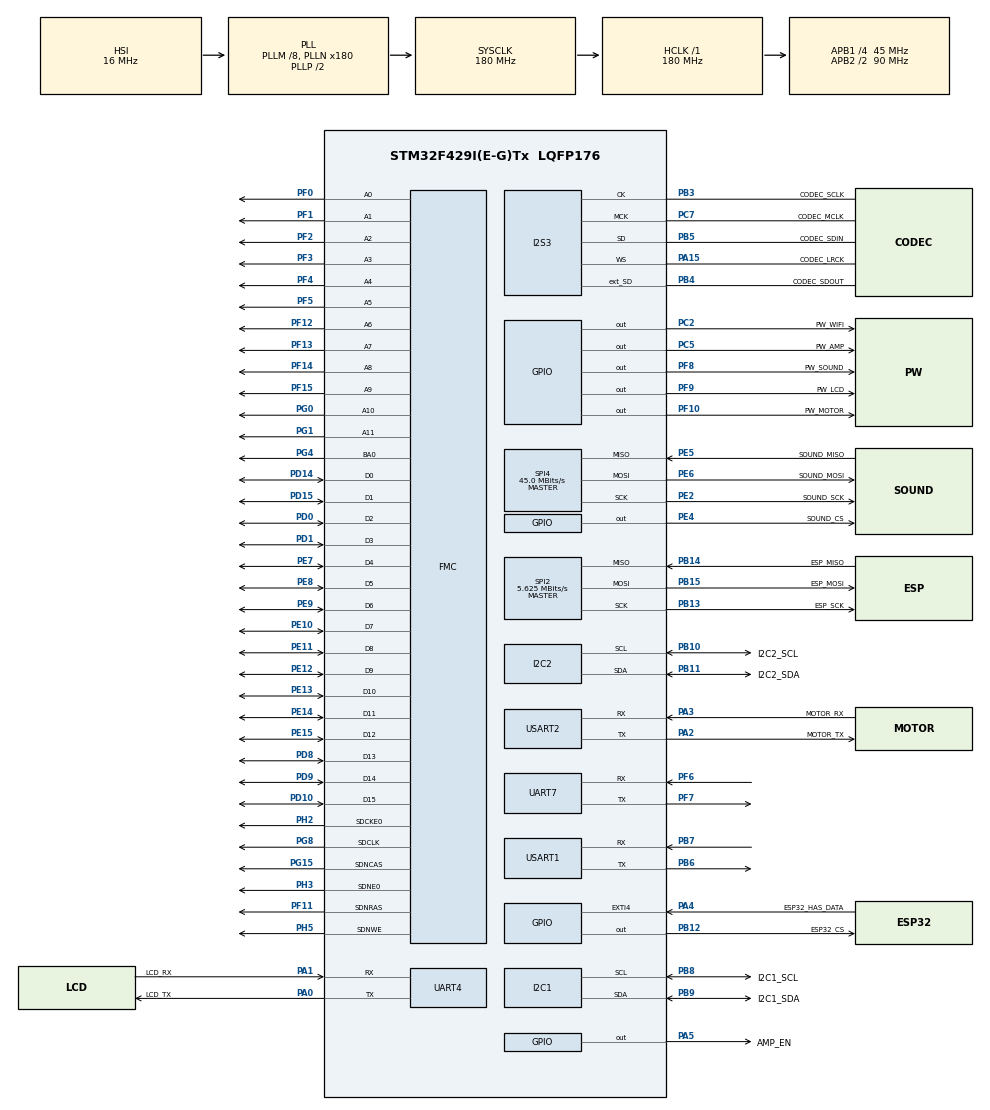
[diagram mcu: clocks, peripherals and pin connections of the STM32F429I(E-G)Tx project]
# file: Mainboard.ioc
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Dma.UART7_TX.4.Priority=DMA_PRIORITY_LOW
Dma.UART7_TX.4.FIFOMode=DMA_FIFOMODE_DISABLE
SH.FMC_D7_DA7.0=FMC_D7,sd-16b-d1
Dma.I2S3_EXT_RX.0.MemDataAlignment=DMA_MDATAALIGN_HALFWORD
SPI4.VirtualType=VM_MASTER
FMC.RCDDelay1=2
FMC.SDClockPeriod1=FMC_SDRAM_CLOCK_PERIOD_3
SH.FMC_A0.0=FMC_A0,12b-sda1
SPI2.VirtualType=VM_MASTER
PB10.Mode=I2C
PG4.Signal=FMC_A14_BA0
PG8.Signal=FMC_SDCLK
PB14.GPIO_Label=ESP_MISO
PG0.Signal=FMC_A10
PA3.GPIO_PuPd=GPIO_PULLUP
FMC.LoadToActiveDelay1=2
SH.FMC_D5_DA5.0=FMC_D5,sd-16b-d1
PB13.Signal=SPI2_SCK
PB3.GPIO_Speed=GPIO_SPEED_FREQ_HIGH
PE6.GPIO_Label=SOUND_MOSI
RCC.SYSCLKSource=RCC_SYSCLKSOURCE_PLLCLK
SH.FMC_D9_DA9.0=FMC_D9,sd-16b-d1
Dma.I2S3_EXT_RX.0.Direction=DMA_PERIPH_TO_MEMORY
PH5.Signal=FMC_SDNWE
PF7.Signal=UART7_TX
SH.FMC_SDNWE.0=FMC_SDNWE,12b-sda1
Dma.SPI2_RX.2.Direction=DMA_PERIPH_TO_MEMORY
SH.FMC_D11_DA11.0=FMC_D11,sd-16b-d1
Dma.UART7_TX.4.Mode=DMA_NORMAL
PE2.Mode=Full_Duplex_Master
RCC.APB2TimFreq_Value=180000000
PB6.Signal=USART1_TX
PC7.Signal=I2S3_MCK
PB12.PinState=GPIO_PIN_SET
PB6.Mode=Asynchronous
PD0.Signal=FMC_D2_DA2
PD8.Signal=FMC_D13_DA13
PE5.Signal=SPI4_MISO
Dma.I2S3_EXT_RX.0.Mode=DMA_CIRCULAR
PF10.GPIO_Label=PW_MOTOR
Dma.SPI2_RX.2.MemDataAlignment=DMA_MDATAALIGN_BYTE
Dma.UART7_TX.4.MemDataAlignment=DMA_MDATAALIGN_BYTE
PB3.Mode=Full_Duplex_Master
Dma.SPI2_RX.2.PeriphInc=DMA_PINC_DISABLE
PB12.GPIO_Label=ESP32_CS
FMC.SelfRefreshTime1=4
I2S3.ErrorAudioFreq=1.72 %
PE9.Signal=FMC_D6_DA6
SH.FMC_A2.0=FMC_A2,12b-sda1
PB14.Mode=Full_Duplex_Master
NVIC.TIM2_IRQn=true\:0\:0\:false\:false\:true\:false\:false\:true
PE4.GPIO_Label=SOUND_CS
SPI2.CalculateBaudRate=5.625 MBits/s
PE2.Signal=SPI4_SCK
Dma.SPI2_RX.2.PeriphDataAlignment=DMA_PDATAALIGN_BYTE
SH.FMC_D1_DA1.0=FMC_D1,sd-16b-d1
PF3.Signal=FMC_A3
PE10.Signal=FMC_D7_DA7
Dma.UART7_TX.4.Direction=DMA_MEMORY_TO_PERIPH
Mcu.Package=LQFP176
PB9.Signal=I2C1_SDA
VP_SYS_VS_tim2.Mode=TIM2
NVIC.TimeBase=TIM2_IRQn
SPI2.Mode=SPI_MODE_MASTER
Dma.SPI2_RX.2.MemInc=DMA_MINC_ENABLE
NVIC.TimeBaseIP=TIM2
SH.FMC_A1.0=FMC_A1,12b-sda1
PB5.GPIO_Speed=GPIO_SPEED_FREQ_HIGH
PH2.Signal=FMC_SDCKE0
RCC.APB2CLKDivider=RCC_HCLK_DIV2
SH.FMC_SDCLK.0=FMC_SDCLK,12b-sda1
PF14.Signal=FMC_A8
RCC.APB1TimFreq_Value=90000000
Dma.I2S3_EXT_RX.0.Priority=DMA_PRIORITY_LOW
PB13.Mode=Full_Duplex_Master
PA4.GPIO_Label=ESP32_HAS_DATA
PD15.Signal=FMC_D1_DA1
SH.FMC_D3_DA3.0=FMC_D3,sd-16b-d1
Dma.SPI2_TX.3.MemInc=DMA_MINC_ENABLE
Dma.SPI3_TX.1.MemInc=DMA_MINC_ENABLE
NVIC.EXTI4_IRQn=true\:15\:0\:true\:false\:true\:true\:true\:true
SH.FMC_A4.0=FMC_A4,12b-sda1
I2S3.FullDuplexMode=I2S_FULLDUPLEXMODE_ENABLE
Dma.I2S3_EXT_RX.0.Instance=DMA1_Stream0
FREERTOS.Tasks01=defaultTask,24,512,StartDefaultTask,Default,NULL,Dynamic,NULL,NULL
SH.FMC_D10_DA10.0=FMC_D10,sd-16b-d1
PC2.Signal=GPIO_Output
PB11.GPIO_Label=I2C2_SDA
PD1.Signal=FMC_D3_DA3
Dma.SPI3_TX.1.Priority=DMA_PRIORITY_LOW
RCC.APB1CLKDivider=RCC_HCLK_DIV4
UART4.VirtualMode=Asynchronous
PF8.GPIO_Label=PW_SOUND
Dma.SPI2_TX.3.PeriphDataAlignment=DMA_PDATAALIGN_BYTE
PD10.Signal=FMC_D15_DA15
PA3.Mode=Asynchronous
SH.FMC_A3.0=FMC_A3,12b-sda1
PB8.GPIO_Label=I2C1_SCL
FMC.CASLatency1=FMC_SDRAM_CAS_LATENCY_3
Dma.UART7_TX.4.PeriphInc=DMA_PINC_DISABLE
PB11.Mode=I2C
Dma.SPI2_RX.2.FIFOMode=DMA_FIFOMODE_DISABLE
SH.FMC_D15_DA15.0=FMC_D15,sd-16b-d1
Dma.I2S3_EXT_RX.0.PeriphInc=DMA_PINC_DISABLE
Dma.SPI3_TX.1.MemDataAlignment=DMA_MDATAALIGN_HALFWORD
I2S3.VirtualMode=I2S_MODE_MASTER
PA4.GPIO_ModeDefaultEXTI=GPIO_MODE_IT_RISING
Dma.I2S3_EXT_RX.0.FIFOMode=DMA_FIFOMODE_DISABLE
Dma.SPI2_TX.3.Mode=DMA_NORMAL
PA0/WKUP.Mode=Asynchronous
PB10.Signal=I2C2_SCL
PB14.Signal=SPI2_MISO
PA5.Signal=GPIO_Output
I2S3.AudioFreq=I2S_AUDIOFREQ_16K
FMC.ReadBurst1=FMC_SDRAM_RBURST_ENABLE
SH.FMC_A6.0=FMC_A6,12b-sda1
Dma.SPI2_TX.3.Instance=DMA1_Stream4
PA1.Mode=Asynchronous
PE14.Signal=FMC_D11_DA11
PE6.Mode=Full_Duplex_Master
PE15.Signal=FMC_D12_DA12
PB4.GPIO_Label=CODEC_SDOUT
PB15.GPIO_Label=ESP_MOSI
PE8.Signal=FMC_D5_DA5
PA1.GPIO_Label=LCD_RX
PA0/WKUP.GPIO_Label=LCD_TX
PF13.Signal=FMC_A7
PA13.Mode=Serial_Wire
SH.FMC_SDNCAS.0=FMC_SDNCAS,12b-sda1
PE4.GPIO_PuPd=GPIO_PULLUP
PC7.GPIO_Label=CODEC_MCLK
Dma.SPI3_TX.1.PeriphInc=DMA_PINC_DISABLE
PA4.Signal=GPXTI4
PB5.Signal=I2S3_SD
PA5.GPIO_Label=AMP_EN
PE5.GPIO_Label=SOUND_MISO
USART1.VirtualMode=VM_ASYNC
SH.FMC_A5.0=FMC_A5,12b-sda1
ProjectManager.HeapSize=0x200
PF6.Mode=Asynchronous
PF9.Signal=GPIO_Output
NVIC.PriorityGroup=NVIC_PRIORITYGROUP_4
PB8.Mode=I2C
Dma.SPI2_TX.3.PeriphInc=DMA_PINC_DISABLE
Dma.SPI2_TX.3.FIFOMode=DMA_FIFOMODE_DISABLE
PF4.Signal=FMC_A4
Dma.UART7_TX.4.Instance=DMA1_Stream1
I2S3.Instance=SPI$Index
PB12.GPIO_PuPd=GPIO_PULLUP
Mcu.Family=STM32F4
PA2.GPIO_PuPd=GPIO_PULLUP
SH.FMC_A8.0=FMC_A8,12b-sda1
RCC.CortexFreq_Value=180000000
SH.FMC_D14_DA14.0=FMC_D14,sd-16b-d1
SPI4.Direction=SPI_DIRECTION_2LINES
SH.FMC_D6_DA6.0=FMC_D6,sd-16b-d1
PA0/WKUP.Signal=UART4_TX
SH.FMC_A14_BA0.0=FMC_BA0,TwoSdramBanks1
SH.FMC_A11.0=FMC_A11,12b-sda1
PB13.GPIO_Label=ESP_SCK
PB11.Signal=I2C2_SDA
NVIC.DMA1_Stream4_IRQn=true\:5\:0\:false\:false\:true\:true\:false\:true
PB15.Signal=SPI2_MOSI
PG15.Signal=FMC_SDNCAS
ProjectManager.StackSize=0x400
VP_FREERTOS_VS_CMSIS_V2.Mode=CMSIS_V2
PH3.Mode=SdramChipSelect1_1
PA15.GPIO_Label=CODEC_LRCK
SH.FMC_A7.0=FMC_A7,12b-sda1
SPI4.Mode=SPI_MODE_MASTER
RCC.HCLKFreq_Value=180000000
PF12.Signal=FMC_A6
Dma.SPI2_TX.3.Priority=DMA_PRIORITY_LOW
SH.FMC_A10.0=FMC_A10,12b-sda1
RCC.AHBFreq_Value=180000000
SPI2.BaudRatePrescaler=SPI_BAUDRATEPRESCALER_8
Dma.SPI2_RX.2.Instance=DMA1_Stream3
RCC.HSE_VALUE=8000000
PA4.GPIO_PuPd=GPIO_PULLUP
SH.FMC_D8_DA8.0=FMC_D8,sd-16b-d1
FMC.ExitSelfRefreshDelay1=7
FMC.RPDelay1=2
PA15.Mode=Full_Duplex_Master
SH.FMC_D2_DA2.0=FMC_D2,sd-16b-d1
PB4.Mode=Full_Duplex_Master
PE13.Signal=FMC_D10_DA10
PA14.Mode=Serial_Wire
PF11.Signal=FMC_SDNRAS
PB5.Mode=Full_Duplex_Master
PB7.Signal=USART1_RX
NVIC.SPI2_IRQn=true\:5\:0\:false\:false\:true\:true\:true\:true
FMC.ReadPipeDelay1=FMC_SDRAM_RPIPE_DELAY_2
SH.FMC_SDNRAS.0=FMC_SDNRAS,12b-sda1
PE4.Signal=GPIO_Output
SPI4.BaudRatePrescaler=SPI_BAUDRATEPRESCALER_2
FREERTOS.configTOTAL_HEAP_SIZE=131072
SH.FMC_D0_DA0.0=FMC_D0,sd-16b-d1
Dma.SPI2_RX.2.Priority=DMA_PRIORITY_LOW
USART2.VirtualMode=VM_ASYNC
Dma.I2S3_EXT_RX.0.MemInc=DMA_MINC_ENABLE
PA2.GPIO_Label=MOTOR_TX
SH.FMC_A9.0=FMC_A9,12b-sda1
PA15.Signal=I2S3_WS
PF8.Signal=GPIO_Output
SH.FMC_D4_DA4.0=FMC_D4,sd-16b-d1
NVIC.SPI3_IRQn=true\:5\:0\:false\:false\:true\:true\:true\:true
SPI2.CLKPhase=SPI_PHASE_2EDGE
PF5.Signal=FMC_A5
Dma.SPI3_TX.1.Direction=DMA_MEMORY_TO_PERIPH
PB5.GPIO_Label=CODEC_SDIN
Dma.Request2=SPI2_RX
Dma.Request1=SPI3_TX
Dma.Request4=UART7_TX
Dma.Request3=SPI2_TX
NVIC.DMA1_Stream0_IRQn=true\:15\:0\:true\:false\:true\:true\:false\:true
SPI2.Direction=SPI_DIRECTION_2LINES
PF0.Signal=FMC_A0
PC5.Signal=GPIO_Output
PH2.Mode=SdramChipSelect1_1
PE7.Signal=FMC_D4_DA4
Dma.Request0=I2S3_EXT_RX
PE2.GPIO_Label=SOUND_SCK
PC2.GPIO_Label=PW_WIFI
Dma.SPI2_TX.3.Direction=DMA_MEMORY_TO_PERIPH
Dma.I2S3_EXT_RX.0.PeriphDataAlignment=DMA_PDATAALIGN_HALFWORD
PB4.Signal=I2S3_ext_SD
PA3.Signal=USART2_RX
PB3.GPIO_Label=CODEC_SCLK
PB9.GPIO_Label=I2C1_SDA
Dma.SPI2_TX.3.MemDataAlignment=DMA_MDATAALIGN_BYTE
PG1.Signal=FMC_A11
Dma.SPI3_TX.1.FIFOMode=DMA_FIFOMODE_DISABLE
PD9.Signal=FMC_D14_DA14
NVIC.DMA1_Stream1_IRQn=true\:5\:0\:false\:false\:true\:true\:false\:true
UART7.VirtualMode=Asynchronous
NVIC.USART2_IRQn=true\:5\:0\:true\:false\:true\:true\:true\:true
Dma.SPI3_TX.1.Instance=DMA1_Stream5
Dma.SPI2_RX.2.Mode=DMA_NORMAL
Dma.SPI3_TX.1.PeriphDataAlignment=DMA_PDATAALIGN_HALFWORD
PA13.Signal=SYS_JTMS-SWDIO
PF7.Mode=Asynchronous
PF6.Signal=UART7_RX
Dma.SPI3_TX.1.Mode=DMA_CIRCULAR
ProjectManager.TargetToolchain=MDK-ARM V5.27
PB10.GPIO_Label=I2C2_SCL
NVIC.DMA1_Stream5_IRQn=true\:15\:0\:true\:false\:true\:true\:false\:true
SH.FMC_D13_DA13.0=FMC_D13,sd-16b-d1
PB9.Mode=I2C
PF2.Signal=FMC_A2
PF9.GPIO_Label=PW_LCD
PE11.Signal=FMC_D8_DA8
RCC.LSE_VALUE=32768
PA1.Signal=UART4_RX
PB12.GPIO_Speed=GPIO_SPEED_FREQ_VERY_HIGH
board=custom
PC7.GPIO_Speed=GPIO_SPEED_FREQ_HIGH
RCC.VCOOutputFreq_Value=360000000
PB15.Mode=Full_Duplex_Master
PB4.GPIO_Speed=GPIO_SPEED_FREQ_HIGH
RCC.APB2Freq_Value=90000000
Dma.UART7_TX.4.PeriphDataAlignment=DMA_PDATAALIGN_BYTE
PF10.Signal=GPIO_Output
PE5.Mode=Full_Duplex_Master
SH.FMC_D12_DA12.0=FMC_D12,sd-16b-d1
PF15.Signal=FMC_A9
SPI4.CalculateBaudRate=45.0 MBits/s
PF1.Signal=FMC_A1
PE6.Signal=SPI4_MOSI
Mcu.Name=STM32F429I(E-G)Tx
PE12.Signal=FMC_D9_DA9
PA2.Signal=USART2_TX
PD14.Signal=FMC_D0_DA0
RCC.48MHZClocksFreq_Value=90000000
PB3.Signal=I2S3_CK
RCC.SYSCLKFreq_VALUE=180000000
PC5.GPIO_Label=PW_AMP
PA15.GPIO_Speed=GPIO_SPEED_FREQ_HIGH
PB7.Mode=Asynchronous
PA14.Signal=SYS_JTCK-SWCLK
RCC.HSI_VALUE=16000000
Dma.UART7_TX.4.MemInc=DMA_MINC_ENABLE
PH3.Signal=FMC_SDNE0
I2S3.RealAudioFreq=16.276 KHz
RCC.PLLM=8
RCC.PLLN=180
PB8.Signal=I2C1_SCL
PA2.Mode=Asynchronous
NVIC.DMA1_Stream3_IRQn=true\:5\:0\:false\:false\:true\:true\:false\:true
PC7.Mode=Master_Clock_Activated
RCC.APB1Freq_Value=45000000
RCC.PLLI2SN=50
PB12.Signal=GPIO_Output
PA3.GPIO_Label=MOTOR_RX
NVIC.UART7_IRQn=true\:5\:0\:false\:false\:true\:true\:true\:true

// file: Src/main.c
/* USER CODE BEGIN Header */
/**
  ******************************************************************************
  * @file           : main.c
  * @brief          : Main program body
  ******************************************************************************
  * @attention
  *
  * <h2><center>&copy; Copyright (c) 2020 STMicroelectronics.
  * All rights reserved.</center></h2>
  *
  * This software component is licensed by ST under Ultimate Liberty license
  * SLA0044, the "License"; You may not use this file except in compliance with
  * the License. You may obtain a copy of the License at:
  *                             www.st.com/SLA0044
  *
  ******************************************************************************
  */
/* USER CODE END Header */

#include "main.h"
#include "cmsis_os.h"

/* USER CODE BEGIN Includes */
#include "command.h"
#include "constant.h"
#include "esp32.h"
#include "direction.h"
#include "log.h"
#include "lcd.h"
#include "audio_play.h"
#include "motor.h"
#include "voice_command.h"
#include "mfcc.h"
#include "gru.h"
#include "dnn.h"

#ifdef RK_CODEC_ENABLE
#include "es8311.h"
#include "stm32429i_mainboard_audio.h"
#include "Resource/audio_please_repeat.h"
#endif /* RK_CODEC_ENABLE */

#include "SEGGER_RTT.h"
#include "app_cli.h"
#include "vsm_shell.h"
#include "FreeRTOS.h"
#include "stream_buffer.h"
#include "cpu_utils.h"
#include "motor.h"
#include "esp32.h"
#include "voice_command.h"
#include "rk_serial_protocol.h"
#include "rk_serial_protocol_id.h"

/* USER CODE END Includes */

/* USER CODE BEGIN PTD */
#define TAG    "main"
#define BUFFER_SIZE         ((uint32_t)0x0100)
#define WRITE_READ_ADDR     ((uint32_t)0x000)
//#define WRITE_READ_ADDR     ((uint32_t)0x004)
#define REFRESH_COUNT       ((uint32_t)0x056A)   /* SDRAM refresh counter (90MHz SDRAM clock) */
/* USER CODE END PTD */

/* USER CODE BEGIN PD */
#define AUDIO_BUFFER_SIZE           16000
#define MAX_AUDIO_LENGTH            64000
#define AUDIO_SPI_RX_BUFFER_SIZE    (16000)
#define DMA_SPI_RX_BUFFER_SIZE      (4092)
#define PING_PONG_TIMEOUT           (10000)
#define ESP32_KEEP_ALIVE_TIMEOUT    (60000)

#define SDRAM_SIZE                  (8*1024*1024)

typedef uint32_t sram_addr_t;

/* USER CODE END PD */

I2C_HandleTypeDef hi2c1;
I2C_HandleTypeDef hi2c2;

I2S_HandleTypeDef hi2s3;
DMA_HandleTypeDef hdma_i2s3_ext_rx;
DMA_HandleTypeDef hdma_spi3_tx;

SPI_HandleTypeDef hspi2;
SPI_HandleTypeDef hspi4;
DMA_HandleTypeDef hdma_spi2_rx;
DMA_HandleTypeDef hdma_spi2_tx;

UART_HandleTypeDef huart4;
UART_HandleTypeDef huart7;
UART_HandleTypeDef huart1;
UART_HandleTypeDef huart2;
DMA_HandleTypeDef hdma_uart7_tx;

SDRAM_HandleTypeDef hsdram1;

/* Definitions for defaultTask */
osThreadId_t defaultTaskHandle;
const osThreadAttr_t defaultTask_attributes = {
  .name = "defaultTask",
  .priority = (osPriority_t) osPriorityNormal,
  .stack_size = 512 * 4
};
/* USER CODE BEGIN PV */
osThreadId_t task_handle_log;
const osThreadAttr_t voice_task_attributes = {
  .name = "voiceCMD",
  .priority = (osPriority_t) osPriorityLow,
  .stack_size = 512 * 4
};
extern int16_t *audio_buffer_in;

/* Read/Write Buffers */
sram_addr_t aTxBuffer[BUFFER_SIZE];
sram_addr_t aRxBuffer[BUFFER_SIZE];
__IO uint32_t uwWriteReadStatus = 0;
static void Fill_Buffer(sram_addr_t *pBuffer, uint32_t uwBufferLenght, sram_addr_t value)
{
    uint32_t tmpIndex = 0;

    /* Put in global buffer different values */
    for (tmpIndex = 0; tmpIndex < uwBufferLenght; tmpIndex++ )
    {
        pBuffer[tmpIndex] = value;
    }
}
static void SDRAM_Initialization_Sequence(SDRAM_HandleTypeDef *hsdram, FMC_SDRAM_CommandTypeDef *Command);
FMC_SDRAM_CommandTypeDef command;

/* Counter index */
uint32_t uwIndex = 0;
/**
 * @brief the buffer stores audio stream
*/
int16_t *audio_buffer_1s;
extern VAD_ResultTypeDef vad_result;

void Assert_Is_NULL(void* value);

/* USER CODE END PV */

void SystemClock_Config(void);
static void MX_GPIO_Init(void);
static void MX_DMA_Init(void);
static void MX_FMC_Init(void);
static void MX_I2C1_Init(void);
static void MX_I2C2_Init(void);
static void MX_SPI2_Init(void);
static void MX_SPI4_Init(void);
static void MX_UART4_Init(void);
static void MX_USART1_UART_Init(void);
static void MX_USART2_UART_Init(void);
static void MX_I2S3_Init(void);
static void MX_UART7_Init(void);
void StartDefaultTask(void *argument);

/* USER CODE BEGIN PFP */
static void task_uart(void * argument);
static void esp32_on_data_callback(uint8_t id, uint8_t len, uint8_t * data);
/* USER CODE END PFP */

/* USER CODE BEGIN 0 */
/**
 * @brief The buffer used to send a command to motor's module
 */
uint8_t Motor_Command_TX[CMD_UART_MAX_LENGTH];

/**
 * @brief The buffer used to send a command to eye's module
 */
uint8_t Eye_Command_TX[CMD_UART_MAX_LENGTH];

static volatile uint32_t success = 0;
static void sdram_test_loop()
{
    vTaskDelay(2000);
    //#define SDRAM_BANK_ADDR 0xD0000000
    #define SDRAM_BANK_ADDR 0xC0000000
    Fill_Buffer(aTxBuffer, BUFFER_SIZE, 0x1234);
    RK_LOGI(TAG, "RAM size %d, test buffer size %d, filter count %d\r\n", SDRAM_SIZE, BUFFER_SIZE*sizeof(sram_addr_t), (SDRAM_SIZE/(BUFFER_SIZE*sizeof(sram_addr_t)) - 1));
    while(1)
    {
        sram_addr_t * pTest = (sram_addr_t*)(SDRAM_BANK_ADDR + WRITE_READ_ADDR);
        for (uint32_t idx = 0; idx < (SDRAM_SIZE/(BUFFER_SIZE*sizeof(sram_addr_t)) - 1); idx++)
        {
          /* Write data to the SDRAM memory */
          for (uwIndex = 0; uwIndex < BUFFER_SIZE; uwIndex++)
          {
            *(__IO sram_addr_t*) (pTest + uwIndex*sizeof(sram_addr_t) + idx*BUFFER_SIZE*sizeof(sram_addr_t)) = aTxBuffer[uwIndex];
          }

          /* Read back data from the SDRAM memory */
          for (uwIndex = 0; uwIndex < BUFFER_SIZE; uwIndex++)
          {
            aRxBuffer[uwIndex] = *(__IO sram_addr_t*) (pTest + uwIndex*sizeof(sram_addr_t) + idx*BUFFER_SIZE*sizeof(sram_addr_t));
           }

          /*##-3- Checking data integrity ############################################*/

    //      for (uwIndex = 0; (uwIndex < BUFFER_SIZE) && (uwWriteReadStatus == 0); uwIndex++)
          for (uwIndex = 0; (uwIndex < BUFFER_SIZE); uwIndex++)
          {
            if (aRxBuffer[uwIndex] != aTxBuffer[uwIndex])
            {
              uwWriteReadStatus++;
            }
          }

          if (uwWriteReadStatus)
          {
            /* KO */
            /* Turn on LED4 */
            RK_LOGI(TAG, "SDRAM verify error count %d\r\n", uwWriteReadStatus);
            assert_failed(__FILE__, __LINE__);
          }
          else
          {
            /* OK */
            /* Turn on LED3 */
              success++;
              static uint32_t j = 0;
              if (j++ == 2000)
              {
                  j = 0;
                  RK_LOGI(TAG, "SDRAM loop : %d\r\n", success);
              }
          }
        }
        vTaskDelay(1);
    }
}

void cli_get_char(void);

/* USER CODE END 0 */

int main(void)
{
  /* USER CODE BEGIN 1 */
    uwTickPrio = TICK_INT_PRIORITY;     // Workaround for stm32 bug
    /* https://community.st.com/s/question/0D50X0000C6duTo/halnvicsetpriority-assert-issue-and-incorrect-preempt-priority-value-for-the-stm32f4-stm32g4- */
  /* USER CODE END 1 */

  /* MCU Configuration--------------------------------------------------------*/

  /* Reset of all peripherals, Initializes the Flash interface and the Systick. */
  HAL_Init();

  /* Configure the system clock */
  SystemClock_Config();

  /* Initialize all configured peripherals */
  MX_GPIO_Init();
  MX_DMA_Init();
  MX_FMC_Init();
  MX_I2C1_Init();
  MX_I2C2_Init();
  MX_SPI2_Init();
  MX_SPI4_Init();
  MX_UART4_Init();
  MX_USART1_UART_Init();
  MX_USART2_UART_Init();
  MX_I2S3_Init();
  MX_UART7_Init();
  /* USER CODE BEGIN 2 */

	audio_buffer_1s = pvPortMalloc(SAMPLE_1_SEC *2);
  Assert_Is_NULL(audio_buffer_1s);

	esp32_spi_communication_initialize();
  KWS_Init();
  /* USER CODE END 2 */

  /* Init scheduler */
  osKernelInitialize();

  /* Create the thread(s) */
  /* creation of defaultTask */
  defaultTaskHandle = osThreadNew(StartDefaultTask, NULL, &defaultTask_attributes);

  /* USER CODE BEGIN RTOS_THREADS */
  task_handle_log = osThreadNew(task_uart, NULL, &voice_task_attributes);

  /* add threads, ... */
  /* USER CODE END RTOS_THREADS */

  /* Start scheduler */
  osKernelStart();

  /* We should never get here as control is now taken by the scheduler */
  /* Infinite loop */
  while (1)
  {

  }
}

void SystemClock_Config(void)
{
  RCC_OscInitTypeDef RCC_OscInitStruct = {0};
  RCC_ClkInitTypeDef RCC_ClkInitStruct = {0};
  RCC_PeriphCLKInitTypeDef PeriphClkInitStruct = {0};

  /** Configure the main internal regulator output voltage
  */
  __HAL_RCC_PWR_CLK_ENABLE();
  __HAL_PWR_VOLTAGESCALING_CONFIG(PWR_REGULATOR_VOLTAGE_SCALE1);
  /** Initializes the CPU, AHB and APB busses clocks
  */
  RCC_OscInitStruct.OscillatorType = RCC_OSCILLATORTYPE_HSI;
  RCC_OscInitStruct.HSIState = RCC_HSI_ON;
  RCC_OscInitStruct.HSICalibrationValue = RCC_HSICALIBRATION_DEFAULT;
  RCC_OscInitStruct.PLL.PLLState = RCC_PLL_ON;
  RCC_OscInitStruct.PLL.PLLSource = RCC_PLLSOURCE_HSI;
  RCC_OscInitStruct.PLL.PLLM = 8;
  RCC_OscInitStruct.PLL.PLLN = 180;
  RCC_OscInitStruct.PLL.PLLP = RCC_PLLP_DIV2;
  RCC_OscInitStruct.PLL.PLLQ = 4;
  if (HAL_RCC_OscConfig(&RCC_OscInitStruct) != HAL_OK)
  {
    Error_Handler();
  }
  /** Activate the Over-Drive mode
  */
  if (HAL_PWREx_EnableOverDrive() != HAL_OK)
  {
    Error_Handler();
  }
  /** Initializes the CPU, AHB and APB busses clocks
  */
  RCC_ClkInitStruct.ClockType = RCC_CLOCKTYPE_HCLK|RCC_CLOCKTYPE_SYSCLK
                              |RCC_CLOCKTYPE_PCLK1|RCC_CLOCKTYPE_PCLK2;
  RCC_ClkInitStruct.SYSCLKSource = RCC_SYSCLKSOURCE_PLLCLK;
  RCC_ClkInitStruct.AHBCLKDivider = RCC_SYSCLK_DIV1;
  RCC_ClkInitStruct.APB1CLKDivider = RCC_HCLK_DIV4;
  RCC_ClkInitStruct.APB2CLKDivider = RCC_HCLK_DIV2;

  if (HAL_RCC_ClockConfig(&RCC_ClkInitStruct, FLASH_LATENCY_5) != HAL_OK)
  {
    Error_Handler();
  }
  PeriphClkInitStruct.PeriphClockSelection = RCC_PERIPHCLK_I2S;
  PeriphClkInitStruct.PLLI2S.PLLI2SN = 50;
  PeriphClkInitStruct.PLLI2S.PLLI2SR = 2;
  if (HAL_RCCEx_PeriphCLKConfig(&PeriphClkInitStruct) != HAL_OK)
  {
    Error_Handler();
  }
}

static void MX_I2C1_Init(void)
{

  hi2c1.Instance = I2C1;
  hi2c1.Init.ClockSpeed = 100000;
  hi2c1.Init.DutyCycle = I2C_DUTYCYCLE_2;
  hi2c1.Init.OwnAddress1 = 0;
  hi2c1.Init.AddressingMode = I2C_ADDRESSINGMODE_7BIT;
  hi2c1.Init.DualAddressMode = I2C_DUALADDRESS_DISABLE;
  hi2c1.Init.OwnAddress2 = 0;
  hi2c1.Init.GeneralCallMode = I2C_GENERALCALL_DISABLE;
  hi2c1.Init.NoStretchMode = I2C_NOSTRETCH_DISABLE;
  if (HAL_I2C_Init(&hi2c1) != HAL_OK)
  {
    Error_Handler();
  }
  /** Configure Analogue filter
  */
  if (HAL_I2CEx_ConfigAnalogFilter(&hi2c1, I2C_ANALOGFILTER_ENABLE) != HAL_OK)
  {
    Error_Handler();
  }
  /** Configure Digital filter
  */
  if (HAL_I2CEx_ConfigDigitalFilter(&hi2c1, 0) != HAL_OK)
  {
    Error_Handler();
  }

}

static void MX_I2C2_Init(void)
{

  hi2c2.Instance = I2C2;
  hi2c2.Init.ClockSpeed = 100000;
  hi2c2.Init.DutyCycle = I2C_DUTYCYCLE_2;
  hi2c2.Init.OwnAddress1 = 0;
  hi2c2.Init.AddressingMode = I2C_ADDRESSINGMODE_7BIT;
  hi2c2.Init.DualAddressMode = I2C_DUALADDRESS_DISABLE;
  hi2c2.Init.OwnAddress2 = 0;
  hi2c2.Init.GeneralCallMode = I2C_GENERALCALL_DISABLE;
  hi2c2.Init.NoStretchMode = I2C_NOSTRETCH_DISABLE;
  if (HAL_I2C_Init(&hi2c2) != HAL_OK)
  {
    Error_Handler();
  }
  /** Configure Analogue filter
  */
  if (HAL_I2CEx_ConfigAnalogFilter(&hi2c2, I2C_ANALOGFILTER_ENABLE) != HAL_OK)
  {
    Error_Handler();
  }
  /** Configure Digital filter
  */
  if (HAL_I2CEx_ConfigDigitalFilter(&hi2c2, 0) != HAL_OK)
  {
    Error_Handler();
  }

}

static void MX_I2S3_Init(void)
{

  hi2s3.Instance = SPI3;
  hi2s3.Init.Mode = I2S_MODE_MASTER_TX;
  hi2s3.Init.Standard = I2S_STANDARD_PHILIPS;
  hi2s3.Init.DataFormat = I2S_DATAFORMAT_16B;
  hi2s3.Init.MCLKOutput = I2S_MCLKOUTPUT_ENABLE;
  hi2s3.Init.AudioFreq = I2S_AUDIOFREQ_16K;
  hi2s3.Init.CPOL = I2S_CPOL_LOW;
  hi2s3.Init.ClockSource = I2S_CLOCK_PLL;
  hi2s3.Init.FullDuplexMode = I2S_FULLDUPLEXMODE_ENABLE;
  if (HAL_I2S_Init(&hi2s3) != HAL_OK)
  {
    Error_Handler();
  }

}

static void MX_SPI2_Init(void)
{

  /* SPI2 parameter configuration*/
  hspi2.Instance = SPI2;
  hspi2.Init.Mode = SPI_MODE_MASTER;
  hspi2.Init.Direction = SPI_DIRECTION_2LINES;
  hspi2.Init.DataSize = SPI_DATASIZE_8BIT;
  hspi2.Init.CLKPolarity = SPI_POLARITY_LOW;
  hspi2.Init.CLKPhase = SPI_PHASE_2EDGE;
  hspi2.Init.NSS = SPI_NSS_SOFT;
  hspi2.Init.BaudRatePrescaler = SPI_BAUDRATEPRESCALER_8;
  hspi2.Init.FirstBit = SPI_FIRSTBIT_MSB;
  hspi2.Init.TIMode = SPI_TIMODE_DISABLE;
  hspi2.Init.CRCCalculation = SPI_CRCCALCULATION_DISABLE;
  hspi2.Init.CRCPolynomial = 10;
  if (HAL_SPI_Init(&hspi2) != HAL_OK)
  {
    Error_Handler();
  }

}

static void MX_SPI4_Init(void)
{

  /* SPI4 parameter configuration*/
  hspi4.Instance = SPI4;
  hspi4.Init.Mode = SPI_MODE_MASTER;
  hspi4.Init.Direction = SPI_DIRECTION_2LINES;
  hspi4.Init.DataSize = SPI_DATASIZE_8BIT;
  hspi4.Init.CLKPolarity = SPI_POLARITY_LOW;
  hspi4.Init.CLKPhase = SPI_PHASE_1EDGE;
  hspi4.Init.NSS = SPI_NSS_SOFT;
  hspi4.Init.BaudRatePrescaler = SPI_BAUDRATEPRESCALER_2;
  hspi4.Init.FirstBit = SPI_FIRSTBIT_MSB;
  hspi4.Init.TIMode = SPI_TIMODE_DISABLE;
  hspi4.Init.CRCCalculation = SPI_CRCCALCULATION_DISABLE;
  hspi4.Init.CRCPolynomial = 10;
  if (HAL_SPI_Init(&hspi4) != HAL_OK)
  {
    Error_Handler();
  }

}

static void MX_UART4_Init(void)
{

  huart4.Instance = UART4;
  huart4.Init.BaudRate = 115200;
  huart4.Init.WordLength = UART_WORDLENGTH_8B;
  huart4.Init.StopBits = UART_STOPBITS_1;
  huart4.Init.Parity = UART_PARITY_NONE;
  huart4.Init.Mode = UART_MODE_TX_RX;
  huart4.Init.HwFlowCtl = UART_HWCONTROL_NONE;
  huart4.Init.OverSampling = UART_OVERSAMPLING_16;
  if (HAL_UART_Init(&huart4) != HAL_OK)
  {
    Error_Handler();
  }

}

static void MX_UART7_Init(void)
{

  huart7.Instance = UART7;
  huart7.Init.BaudRate = 115200;
  huart7.Init.WordLength = UART_WORDLENGTH_8B;
  huart7.Init.StopBits = UART_STOPBITS_1;
  huart7.Init.Parity = UART_PARITY_NONE;
  huart7.Init.Mode = UART_MODE_TX_RX;
  huart7.Init.HwFlowCtl = UART_HWCONTROL_NONE;
  huart7.Init.OverSampling = UART_OVERSAMPLING_16;
  if (HAL_UART_Init(&huart7) != HAL_OK)
  {
    Error_Handler();
  }

}

static void MX_USART1_UART_Init(void)
{

  huart1.Instance = USART1;
  huart1.Init.BaudRate = 115200;
  huart1.Init.WordLength = UART_WORDLENGTH_8B;
  huart1.Init.StopBits = UART_STOPBITS_1;
  huart1.Init.Parity = UART_PARITY_NONE;
  huart1.Init.Mode = UART_MODE_TX_RX;
  huart1.Init.HwFlowCtl = UART_HWCONTROL_NONE;
  huart1.Init.OverSampling = UART_OVERSAMPLING_16;
  if (HAL_UART_Init(&huart1) != HAL_OK)
  {
    Error_Handler();
  }

}

static void MX_USART2_UART_Init(void)
{

  huart2.Instance = USART2;
  huart2.Init.BaudRate = 115200;
  huart2.Init.WordLength = UART_WORDLENGTH_8B;
  huart2.Init.StopBits = UART_STOPBITS_1;
  huart2.Init.Parity = UART_PARITY_NONE;
  huart2.Init.Mode = UART_MODE_TX_RX;
  huart2.Init.HwFlowCtl = UART_HWCONTROL_NONE;
  huart2.Init.OverSampling = UART_OVERSAMPLING_16;
  if (HAL_UART_Init(&huart2) != HAL_OK)
  {
    Error_Handler();
  }

}

static void MX_DMA_Init(void)
{

  /* DMA controller clock enable */
  __HAL_RCC_DMA1_CLK_ENABLE();

  /* DMA interrupt init */
  /* DMA1_Stream0_IRQn interrupt configuration */
  HAL_NVIC_SetPriority(DMA1_Stream0_IRQn, 15, 0);
  HAL_NVIC_EnableIRQ(DMA1_Stream0_IRQn);
  /* DMA1_Stream1_IRQn interrupt configuration */
  HAL_NVIC_SetPriority(DMA1_Stream1_IRQn, 5, 0);
  HAL_NVIC_EnableIRQ(DMA1_Stream1_IRQn);
  /* DMA1_Stream3_IRQn interrupt configuration */
  HAL_NVIC_SetPriority(DMA1_Stream3_IRQn, 5, 0);
  HAL_NVIC_EnableIRQ(DMA1_Stream3_IRQn);
  /* DMA1_Stream4_IRQn interrupt configuration */
  HAL_NVIC_SetPriority(DMA1_Stream4_IRQn, 5, 0);
  HAL_NVIC_EnableIRQ(DMA1_Stream4_IRQn);
  /* DMA1_Stream5_IRQn interrupt configuration */
  HAL_NVIC_SetPriority(DMA1_Stream5_IRQn, 15, 0);
  HAL_NVIC_EnableIRQ(DMA1_Stream5_IRQn);

}

/* FMC initialization function */
static void MX_FMC_Init(void)
{

  /* USER CODE BEGIN FMC_Init 0 */
#if 1
  /* USER CODE END FMC_Init 0 */

  FMC_SDRAM_TimingTypeDef SdramTiming = {0};

  /** Perform the SDRAM1 memory initialization sequence
  */
  hsdram1.Instance = FMC_SDRAM_DEVICE;
  /* hsdram1.Init */
  hsdram1.Init.SDBank = FMC_SDRAM_BANK1;
  hsdram1.Init.ColumnBitsNumber = FMC_SDRAM_COLUMN_BITS_NUM_8;
  hsdram1.Init.RowBitsNumber = FMC_SDRAM_ROW_BITS_NUM_12;
  hsdram1.Init.MemoryDataWidth = FMC_SDRAM_MEM_BUS_WIDTH_16;
  hsdram1.Init.InternalBankNumber = FMC_SDRAM_INTERN_BANKS_NUM_4;
  hsdram1.Init.CASLatency = FMC_SDRAM_CAS_LATENCY_3;
  hsdram1.Init.WriteProtection = FMC_SDRAM_WRITE_PROTECTION_DISABLE;
  hsdram1.Init.SDClockPeriod = FMC_SDRAM_CLOCK_PERIOD_3;
  hsdram1.Init.ReadBurst = FMC_SDRAM_RBURST_ENABLE;
  hsdram1.Init.ReadPipeDelay = FMC_SDRAM_RPIPE_DELAY_2;
  /* SdramTiming */
  SdramTiming.LoadToActiveDelay = 2;
  SdramTiming.ExitSelfRefreshDelay = 7;
  SdramTiming.SelfRefreshTime = 4;
  SdramTiming.RowCycleDelay = 16;
  SdramTiming.WriteRecoveryTime = 16;
  SdramTiming.RPDelay = 2;
  SdramTiming.RCDDelay = 2;

  if (HAL_SDRAM_Init(&hsdram1, &SdramTiming) != HAL_OK)
  {
    Error_Handler( );
  }

  /* USER CODE BEGIN FMC_Init 2 */
  /* Program the SDRAM external device */
  SDRAM_Initialization_Sequence(&hsdram1, &command);
#endif /* SDRAM_ENABLE */
  /* USER CODE END FMC_Init 2 */
}

static void MX_GPIO_Init(void)
{
  GPIO_InitTypeDef GPIO_InitStruct = {0};

  /* GPIO Ports Clock Enable */
  __HAL_RCC_GPIOE_CLK_ENABLE();
  __HAL_RCC_GPIOF_CLK_ENABLE();
  __HAL_RCC_GPIOC_CLK_ENABLE();
  __HAL_RCC_GPIOA_CLK_ENABLE();
  __HAL_RCC_GPIOH_CLK_ENABLE();
  __HAL_RCC_GPIOG_CLK_ENABLE();
  __HAL_RCC_GPIOB_CLK_ENABLE();
  __HAL_RCC_GPIOD_CLK_ENABLE();

  /*Configure GPIO pin Output Level */
  HAL_GPIO_WritePin(SOUND_CS_GPIO_Port, SOUND_CS_Pin, GPIO_PIN_RESET);

  /*Configure GPIO pin Output Level */
  HAL_GPIO_WritePin(GPIOF, PW_SOUND_Pin|PW_LCD_Pin|PW_MOTOR_Pin, GPIO_PIN_RESET);

  /*Configure GPIO pin Output Level */
  HAL_GPIO_WritePin(GPIOC, PW_WIFI_Pin|PW_AMP_Pin, GPIO_PIN_RESET);

  /*Configure GPIO pin Output Level */
  HAL_GPIO_WritePin(AMP_EN_GPIO_Port, AMP_EN_Pin, GPIO_PIN_RESET);

  /*Configure GPIO pin Output Level */
  HAL_GPIO_WritePin(ESP32_CS_GPIO_Port, ESP32_CS_Pin, GPIO_PIN_SET);

  /*Configure GPIO pin : SOUND_CS_Pin */
  GPIO_InitStruct.Pin = SOUND_CS_Pin;
  GPIO_InitStruct.Mode = GPIO_MODE_OUTPUT_PP;
  GPIO_InitStruct.Pull = GPIO_PULLUP;
  GPIO_InitStruct.Speed = GPIO_SPEED_FREQ_LOW;
  HAL_GPIO_Init(SOUND_CS_GPIO_Port, &GPIO_InitStruct);

  /*Configure GPIO pins : PW_SOUND_Pin PW_LCD_Pin PW_MOTOR_Pin */
  GPIO_InitStruct.Pin = PW_SOUND_Pin|PW_LCD_Pin|PW_MOTOR_Pin;
  GPIO_InitStruct.Mode = GPIO_MODE_OUTPUT_PP;
  GPIO_InitStruct.Pull = GPIO_NOPULL;
  GPIO_InitStruct.Speed = GPIO_SPEED_FREQ_LOW;
  HAL_GPIO_Init(GPIOF, &GPIO_InitStruct);

  /*Configure GPIO pins : PW_WIFI_Pin PW_AMP_Pin */
  GPIO_InitStruct.Pin = PW_WIFI_Pin|PW_AMP_Pin;
  GPIO_InitStruct.Mode = GPIO_MODE_OUTPUT_PP;
  GPIO_InitStruct.Pull = GPIO_NOPULL;
  GPIO_InitStruct.Speed = GPIO_SPEED_FREQ_LOW;
  HAL_GPIO_Init(GPIOC, &GPIO_InitStruct);

  /*Configure GPIO pin : ESP32_HAS_DATA_Pin */
  GPIO_InitStruct.Pin = ESP32_HAS_DATA_Pin;
  GPIO_InitStruct.Mode = GPIO_MODE_IT_RISING;
  GPIO_InitStruct.Pull = GPIO_PULLUP;
  HAL_GPIO_Init(ESP32_HAS_DATA_GPIO_Port, &GPIO_InitStruct);

  /*Configure GPIO pin : AMP_EN_Pin */
  GPIO_InitStruct.Pin = AMP_EN_Pin;
  GPIO_InitStruct.Mode = GPIO_MODE_OUTPUT_PP;
  GPIO_InitStruct.Pull = GPIO_NOPULL;
  GPIO_InitStruct.Speed = GPIO_SPEED_FREQ_LOW;
  HAL_GPIO_Init(AMP_EN_GPIO_Port, &GPIO_InitStruct);

  /*Configure GPIO pin : ESP32_CS_Pin */
  GPIO_InitStruct.Pin = ESP32_CS_Pin;
  GPIO_InitStruct.Mode = GPIO_MODE_OUTPUT_PP;
  GPIO_InitStruct.Pull = GPIO_PULLUP;
  GPIO_InitStruct.Speed = GPIO_SPEED_FREQ_VERY_HIGH;
  HAL_GPIO_Init(ESP32_CS_GPIO_Port, &GPIO_InitStruct);

  /* EXTI interrupt init*/
  HAL_NVIC_SetPriority(EXTI4_IRQn, 15, 0);
  HAL_NVIC_EnableIRQ(EXTI4_IRQn);

}

/* USER CODE BEGIN 4 */

void cli_get_char()
{
    int key = SEGGER_RTT_GetKey();
    if (key < 0)
    {
        return;
    }
    uint8_t val = (uint8_t)key;
    cli_input_insert(&val, 1);
}

void HAL_GPIO_EXTI_Callback(uint16_t GPIO_Pin) {
    if (GPIO_Pin == GPIO_PIN_4)
    {
//        RK_LOGI(TAG, "Handshake level %s\r\n", HAL_GPIO_ReadPin(GPIOA, GPIO_PIN_4) ? "high" : "low");
        if (HAL_GPIO_ReadPin(GPIOA, GPIO_PIN_4))
            esp32_notify_slave_ready(true);
        else
            esp32_notify_slave_busy();
    }
}

void HAL_UART_ErrorCallback(UART_HandleTypeDef *huart)
{
    __HAL_UART_CLEAR_OREFLAG(huart);
    __HAL_UART_CLEAR_NEFLAG(huart);
    __HAL_UART_CLEAR_FEFLAG(huart);
//    __HAL_UART_DISABLE_IT(huart, UART_IT_ERR);

    if (huart == &huart7)
    {
        esp32_uart_rx_enable(); //TODO:
    }
    else if (huart == &huart2)
    {
        motor_uart_rx_enable();
    }
    else if (huart == &huart4)
    {
        lcd_uart_rx_enable();
    }
}

void HAL_UART_TxCpltCallback(UART_HandleTypeDef *huart)
{
	if (huart == &huart2)
    {
//		free(huart->pTxBuffPtr);
        motor_cmd_done_cb();
	}
    else if (huart == &huart7)
    {
        esp32_cmd_uart_tx_done();
    }
    else if (huart == &huart4)
    {
        lcd_cmd_done_cb();
    }
}

void HAL_UART_RxCpltCallback(UART_HandleTypeDef *huart)
{
    if (huart == &huart7)
    {
//        uint8_t recv = esp32_communication_get_last_in_data();
        esp32_communication_rx_data(true);
        esp32_uart_rx_enable();
    }
    else
        if (huart == &huart2)
    {
        motor_uart_rx_enable();
	}
    else if (huart == &huart4)
    {
        uint8_t recv = lcd_uart_get_last_in_data();
        lcd_uart_rx_enable();
    }
}

//void HAL_SPI_RxCpltCallback(SPI_HandleTypeDef *hspi)
void HAL_SPI_TxRxCpltCallback(SPI_HandleTypeDef *hspi)
{
//    RK_LOGE(TAG, "HAL_SPI_RxCpltCallback\r\n");
    if (hspi == &hspi2)
    {
        esp32_signal_spi_done(true);
    }
}

void HAL_SPI_RxHalfCpltCallback(SPI_HandleTypeDef *hspi)
{
//    RK_LOGE(TAG, "HAL_SPI_RxHalfCpltCallback\r\n");
//    if (hspi == &hspi2)
//    {
//        BaseType_t ctx_sw;
//        if (xStreamBufferSendFromISR(m_spi_rx_stream_buffer, g_spi_rx_buffer, DMA_SPI_RX_BUFFER_SIZE/2, &ctx_sw) == 0)
//        {
//            RK_LOGE(TAG, "SPI RX queue full\r\n");
//            app_error_handler(__FILE__, __LINE__, 1);
//        }
//        portYIELD_FROM_ISR(ctx_sw);
//    }
}

void HAL_SPI_ErrorCallback(SPI_HandleTypeDef *hspi)
{
  	if(hspi->Instance == SPI2){
  		app_error_handler(__FILE__, __LINE__, 1);

//        #define HAL_SPI_ERROR_NONE              (0x00000000U)   /*!< No error                               */
//        #define HAL_SPI_ERROR_MODF              (0x00000001U)   /*!< MODF error                             */
//        #define HAL_SPI_ERROR_CRC               (0x00000002U)   /*!< CRC error                              */
//        #define HAL_SPI_ERROR_OVR               (0x00000004U)   /*!< OVR error                              */
//        #define HAL_SPI_ERROR_FRE               (0x00000008U)   /*!< FRE error                              */
//        #define HAL_SPI_ERROR_DMA               (0x00000010U)   /*!< DMA transfer error                     */
//        #define HAL_SPI_ERROR_FLAG              (0x00000020U)   /*!< Error on RXNE/TXE/BSY Flag             */
//        #define HAL_SPI_ERROR_ABORT             (0x00000040U)   /*!< Error during SPI Abort procedure       */
        volatile uint32_t spi_data_register =  hspi2.Instance->DR; // To clear over run
        RK_LOGI(TAG, "HAL_SPI_ErrorCallback : error code [0x%02X], CS %s\r\n",
                hspi->ErrorCode,
                HAL_GPIO_ReadPin(GPIOB, GPIO_PIN_12) ? "high" : "low"); // CS signal);
//
//        while(!HAL_GPIO_ReadPin(GPIOB, GPIO_PIN_12));
//        __disable_irq();
//        HAL_SPI_Abort(&hspi2);
//        __enable_irq();
//        while(HAL_GPIO_ReadPin(GPIOB, GPIO_PIN_12) != GPIO_PIN_SET) // CS signal
//        {
//        }

//    __disable_irq();
////    /* might not be necessary */

////    hspi2.hdmarx->XferCpltCallback = NULL;
//    HAL_SPI_Abort(&hspi2);
//    __enable_irq();

	}
}

void Assert_Is_NULL(void* value){
	if(value == NULL){
		app_error_handler(__FILE__, __LINE__, (int)ERR_ALLOCATE_MEMORY);
	}
}

/**
  * @brief  Perform the SDRAM exernal memory inialization sequence
  * @param  hsdram: SDRAM handle
  * @param  Command: Pointer to SDRAM command structure
  * @retval None
  */
static void SDRAM_Initialization_Sequence(SDRAM_HandleTypeDef *hsdram, FMC_SDRAM_CommandTypeDef *Command)
{
  __IO uint32_t tmpmrd =0;
  /* Step 3:  Configure a clock configuration enable command */
  Command->CommandMode 			 = FMC_SDRAM_CMD_CLK_ENABLE;
  Command->CommandTarget 		 = FMC_SDRAM_CMD_TARGET_BANK1;
  Command->AutoRefreshNumber 	 = 1;
  Command->ModeRegisterDefinition = 0;

  /* Send the command */
  HAL_SDRAM_SendCommand(hsdram, Command, 0x1000);

  /* Step 4: Insert 100 ms delay */
  HAL_Delay(100);

  /* Step 5: Configure a PALL (precharge all) command */
  Command->CommandMode 			 = FMC_SDRAM_CMD_PALL;
  Command->CommandTarget 	     = FMC_SDRAM_CMD_TARGET_BANK1;
  Command->AutoRefreshNumber 	 = 1;
  Command->ModeRegisterDefinition = 0;

  /* Send the command */
  HAL_SDRAM_SendCommand(hsdram, Command, 0x1000);

  /* Step 6 : Configure a Auto-Refresh command */
  Command->CommandMode 			 = FMC_SDRAM_CMD_AUTOREFRESH_MODE;
  Command->CommandTarget 		 = FMC_SDRAM_CMD_TARGET_BANK1;
  Command->AutoRefreshNumber 	 = 4;
  Command->ModeRegisterDefinition = 0;

  /* Send the command */
  HAL_SDRAM_SendCommand(hsdram, Command, 0x1000);

  /* Step 7: Program the external memory mode register */
    #define SDRAM_MODEREG_BURST_LENGTH_1             ((uint16_t)0x0000)
    #define SDRAM_MODEREG_BURST_LENGTH_2             ((uint16_t)0x0001)
    #define SDRAM_MODEREG_BURST_LENGTH_4             ((uint16_t)0x0002)
    #define SDRAM_MODEREG_BURST_LENGTH_8             ((uint16_t)0x0004)
    #define SDRAM_MODEREG_BURST_TYPE_SEQUENTIAL      ((uint16_t)0x0000)
    #define SDRAM_MODEREG_BURST_TYPE_INTERLEAVED     ((uint16_t)0x0008)
    #define SDRAM_MODEREG_CAS_LATENCY_2              ((uint16_t)0x0020)
    #define SDRAM_MODEREG_CAS_LATENCY_3              ((uint16_t)0x0030)
    #define SDRAM_MODEREG_OPERATING_MODE_STANDARD    ((uint16_t)0x0000)
    #define SDRAM_MODEREG_WRITEBURST_MODE_PROGRAMMED ((uint16_t)0x0000)
    #define SDRAM_MODEREG_WRITEBURST_MODE_SINGLE     ((uint16_t)0x0200)

  tmpmrd = (uint32_t)SDRAM_MODEREG_BURST_LENGTH_2          |
                     SDRAM_MODEREG_BURST_TYPE_SEQUENTIAL   |
                     SDRAM_MODEREG_CAS_LATENCY_3           |
                     SDRAM_MODEREG_OPERATING_MODE_STANDARD |
                     SDRAM_MODEREG_WRITEBURST_MODE_SINGLE;

//    Command->CommandMode = FMC_SDRAM_CMD_LOAD_MODE;
  Command->CommandMode = FMC_SDRAM_CMD_AUTOREFRESH_MODE;
  Command->CommandTarget 		 = FMC_SDRAM_CMD_TARGET_BANK1;
  Command->AutoRefreshNumber 	 = 1;
  Command->ModeRegisterDefinition = tmpmrd;

  /* Send the command */
  HAL_SDRAM_SendCommand(hsdram, Command, 0x1000);

  /* Step 8: Set the refresh rate counter */
  /* (15.62 us x Freq) - 20 */
  /* Set the device refresh counter */
  HAL_SDRAM_ProgramRefreshRate(hsdram, REFRESH_COUNT);
}

/**
 * @brief  This function is executed in case of error occurrence.
 * @retval None
 */
void app_error_handler(char * file, int line, int error_code) {
    RK_LOGE(TAG, "Assert [%d] at file %s, line %d\r\n", error_code, file, line);
    __disable_irq();
    __ASM volatile("BKPT #01");   // insert breakpoint here
	while(true){
	};
}

void vApplicationMallocFailedHook( void )
{
    RK_LOGE(TAG, "Malloc failed\r\n");
    __disable_irq();
    __ASM volatile("BKPT #01");   // insert breakpoint here
	while(true){
	};
}

static uint32_t m_last_seen_esp32 = 0;
static void on_esp32_dead()
{
    // TODO : Long time no see esp32
    // May be esp32 could not boot up
}

static void esp32_on_data_callback(uint8_t id, uint8_t len, uint8_t* data)
{
    RK_LOGI(TAG, "Recv id %d, size %d bytes\r\n", id, len);
    switch (id)
    {
        case RK_ID_SEND_AUDIO_TO_CLOUD:
            break;

        case RK_ID_PING:
            break;

        case RK_ID_PONG:
             RK_LOGI(TAG, "Pong\r\n");
            break;

        case RK_ID_MOTOR_CTRL:
					{
						memset(Motor_Command_TX, 0, CMD_UART_MAX_LENGTH);
						*Motor_Command_TX = *data;
						motor_send(Motor_Command_TX, CMD_UART_MAX_LENGTH);
					}
            break;

        default:
            break;
    }
}

static void task_uart(void * argument)
{
    vTaskDelay(1);
    sdram_test_loop();

    rk_serial_protocol_config_t conf;
    conf.tx_byte = NULL;
    conf.tx_frame = esp32_communication_uart_tx;
    conf.callback = esp32_on_data_callback;
    rk_serial_protocol_init(&conf);

    esp32_uart_communication_initialize();
    uint32_t ping_cnt = xTaskGetTickCount();
//    uint32_t m_last_seen_esp32 = xTaskGetTickCount();
    for(;;)
    {
        bool seen_esp32 = false;
        while(esp32_communication_get_bytes_availble())
        {
            rk_serial_protocol_rx_byte(esp32_communication_get_bytes());
            seen_esp32 = true;
        }

        if (seen_esp32)
        {
            m_last_seen_esp32 = xTaskGetTickCount();
        }
        else
        {
            if (xTaskGetTickCount() - m_last_seen_esp32 > ESP32_KEEP_ALIVE_TIMEOUT)
            {
                on_esp32_dead();
                m_last_seen_esp32 = xTaskGetTickCount();
            }
        }

        if(vad_result == VAD_DETECT_VOICE){
            vTaskDelay(100);
            rk_serial_tx_frame(RK_ID_START_RECORDING, 0, NULL);
            vad_result = VAD_NO_CHANGE;
        }else if(vad_result == VAD_DETECT_SILIENT){
            vTaskDelay(100);
            rk_serial_tx_frame(RK_ID_START_SENDING_AUDIO, 0, NULL);
            vad_result = VAD_NO_CHANGE;
        }

//        if (xTaskGetTickCount() - ping_cnt > PING_PONG_TIMEOUT)
//        {
//            // Do ping
//            // @Note : max frame size is 115 bytes
//            rk_serial_tx_frame(RK_ID_PING, 0, NULL);
//            ping_cnt = xTaskGetTickCount();
//            RK_LOGI(TAG, "Ping\r\n");
//        }

        vTaskDelay(1);
    }
}

/* USER CODE END 4 */

void StartDefaultTask(void *argument)
{
  /* USER CODE BEGIN 5 */
    #define SPI_DMA_RX_WAIT_TIME 50
    RK_LOG_INIT();
    RK_LOGI(TAG, "Build %s\r\n", __DATE__);

    esp32_spi_communication_initialize();
    Direction_Init_Communication();
    motor_init_communication();
    Lcd_Init_Communication();

    /* Infinite loop */
    uint32_t audio_size;
		vTaskDelay(3000);
    uint32_t default_task_tick = xTaskGetTickCount();

    Esp32_Change_Spi_Cs(GPIO_PIN_SET);
    vTaskDelay(30);
    if (HAL_GPIO_ReadPin(GPIOA, GPIO_PIN_4))
    {
        RK_LOGI(TAG, "Slave ready\r\n");
        esp32_notify_slave_ready(false);
    }

     uint32_t start_time = xTaskGetTickCount();
    for(;;)
    {
        vTaskDelayUntil(&default_task_tick, SPI_DMA_RX_WAIT_TIME);
        uint8_t* audio_data = esp32_get_audio_data(10000);
        if(*audio_data == CMD_AUDIO_DATA){
            audio_size = *((uint32_t*)(audio_data + HEADER_OFFSET_REQUEST_DATA_SIZE));
            if(audio_size < SAMPLE_1_SEC*2){
                memmove(audio_buffer_1s, ((uint8_t*)audio_buffer_1s) + audio_size, SAMPLE_1_SEC * 2 - audio_size);
                memcpy(((uint8_t*)audio_buffer_1s) + SAMPLE_1_SEC * 2 - audio_size, audio_data + HEADER_OFFSET_REQUEST_DATA, audio_size);
            }
        }
//        else{
//            RK_LOGI(TAG, "no data\r\n");
//        }
        if(xTaskGetTickCount() - start_time > 200){
            voice_command_fill_buffer(audio_buffer_1s, SAMPLE_1_SEC *2);
            Run_KWS();
            start_time = xTaskGetTickCount();
        }
    }
  /* USER CODE END 5 */
}

 /**
  * @brief  Period elapsed callback in non blocking mode
  * @note   This function is called  when TIM2 interrupt took place, inside
  * HAL_TIM_IRQHandler(). It makes a direct call to HAL_IncTick() to increment
  * a global variable "uwTick" used as application time base.
  * @param  htim : TIM handle
  * @retval None
  */
void HAL_TIM_PeriodElapsedCallback(TIM_HandleTypeDef *htim)
{
  if (htim->Instance == TIM2) {
    HAL_IncTick();
  }
}

void Error_Handler(void)
{
  /* USER CODE BEGIN Error_Handler_Debug */
  /* User can add his own implementation to report the HAL error return state */
    RK_LOGE(TAG, "Error_Handler\r\n");
    __disable_irq();
    __ASM volatile("BKPT #01");   // insert breakpoint here
    while(1);
  /* USER CODE END Error_Handler_Debug */
}

#ifdef  USE_FULL_ASSERT
/**
  * @brief  Reports the name of the source file and the source line number
  *         where the assert_param error has occurred.
  * @param  file: pointer to the source file name
  * @param  line: assert_param error line source number
  * @retval None
  */
void assert_failed(uint8_t *file, uint32_t line)
{
  /* USER CODE BEGIN 6 */
    RK_LOGE(TAG, "Assert failed in file %s, line %d\r\n", (char*)file, line);
    __disable_irq();
    __ASM volatile("BKPT #01");   // insert breakpoint here
    while(1);
	/* User can add his own implementation to report the file name and line number,
	 tex: printf("Wrong parameters value: file %s on line %d\r\n", file, line) */
  /* USER CODE END 6 */
}
#endif /* USE_FULL_ASSERT */

/************************ (C) COPYRIGHT STMicroelectronics *****END OF FILE****/
